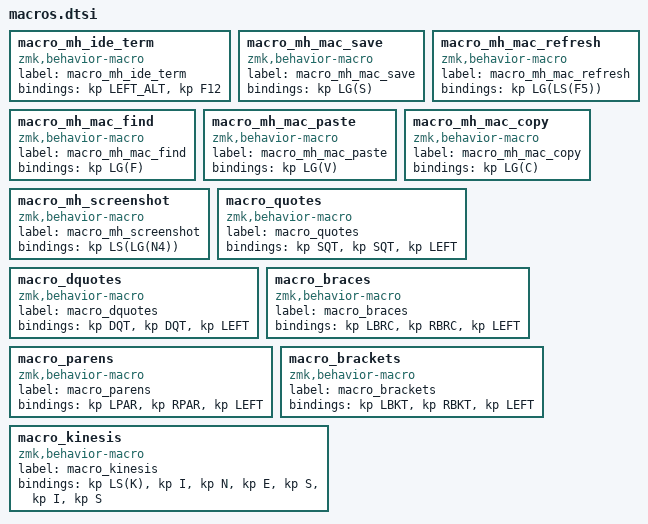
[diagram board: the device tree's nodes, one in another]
macro_mh_ide_term: macro_mh_ide_term{
compatible = "zmk,behavior-macro";
label = "macro_mh_ide_term";
#binding-cells = <0>;
bindings = <&kp LEFT_ALT>, <&kp F12>;
};
macro_mh_mac_save: macro_mh_mac_save{
compatible = "zmk,behavior-macro";
label = "macro_mh_mac_save";
#binding-cells = <0>;
bindings = <&kp LG(S)>;
};
macro_mh_mac_refresh: macro_mh_mac_refresh{
compatible = "zmk,behavior-macro";
label = "macro_mh_mac_refresh";
#binding-cells = <0>;
bindings = <&kp LG(LS(F5))>;
};
macro_mh_mac_find: macro_mh_mac_find{
compatible = "zmk,behavior-macro";
label = "macro_mh_mac_find";
#binding-cells = <0>;
bindings = <&kp LG(F)>;
};
macro_mh_mac_paste: macro_mh_mac_paste{
compatible = "zmk,behavior-macro";
label = "macro_mh_mac_paste";
#binding-cells = <0>;
bindings = <&kp LG(V)>;
};
macro_mh_mac_copy: macro_mh_mac_copy{
compatible = "zmk,behavior-macro";
label = "macro_mh_mac_copy";
#binding-cells = <0>;
bindings = <&kp LG(C)>;
};
macro_mh_screenshot: macro_mh_screenshot{
compatible = "zmk,behavior-macro";
label = "macro_mh_screenshot";
#binding-cells = <0>;
bindings = <&kp LS(LG(N4))>;
};
macro_quotes: macro_quotes{
compatible = "zmk,behavior-macro";
label = "macro_quotes";
#binding-cells = <0>;
bindings = <&kp SQT>, <&kp SQT>, <&kp LEFT>;
};
macro_dquotes: macro_dquotes{
compatible = "zmk,behavior-macro";
label = "macro_dquotes";
#binding-cells = <0>;
bindings = <&kp DQT>, <&kp DQT>, <&kp LEFT>;
};
macro_braces: macro_braces{
compatible = "zmk,behavior-macro";
label = "macro_braces";
#binding-cells = <0>;
bindings = <&kp LBRC>, <&kp RBRC>, <&kp LEFT>;
};
macro_parens: macro_parens{
compatible = "zmk,behavior-macro";
label = "macro_parens";
#binding-cells = <0>;
bindings = <&kp LPAR>, <&kp RPAR>, <&kp LEFT>;
};
macro_brackets: macro_brackets{
compatible = "zmk,behavior-macro";
label = "macro_brackets";
#binding-cells = <0>;
bindings = <&kp LBKT>, <&kp RBKT>, <&kp LEFT>;
};
macro_kinesis: macro_kinesis{
compatible = "zmk,behavior-macro";
label = "macro_kinesis";
#binding-cells = <0>;
bindings = <&kp LS(K)>, <&kp I>, <&kp N>, <&kp E>, <&kp S>, <&kp I>, <&kp S>;
};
